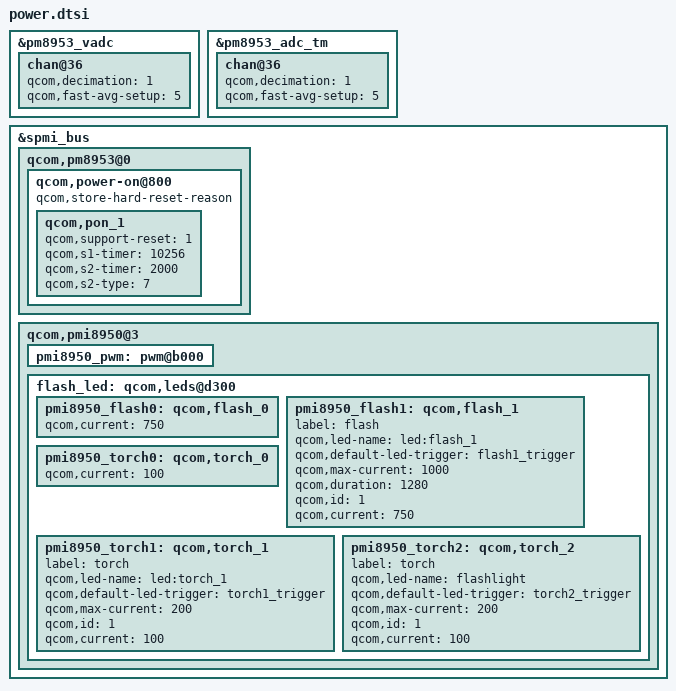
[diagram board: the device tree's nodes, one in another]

/* pm8953.dtsi */
&pm8953_vadc{
	chan@36 {
		qcom,decimation = <1>;
		qcom,fast-avg-setup = <5>;
	};
};
&pm8953_adc_tm{
	chan@36 {
		qcom,decimation = <1>;
		qcom,fast-avg-setup = <5>;
	};
};

&spmi_bus {
    /* pm8953.dtsi */
    /delete-node/ qcom,pm8953_typec@bf00;
	qcom,pm8953@0 {
		qcom,power-on@800 {
			qcom,store-hard-reset-reason;
			qcom,pon_1 {
				qcom,support-reset = <1>;
				qcom,s1-timer = <10256>;
				qcom,s2-timer = <2000>;
				qcom,s2-type = <7>;
		    };
	    };
    };
    /* pmi8950.dtsi */
    qcom,pmi8950@3 {

        pmi8950_pwm: pwm@b000 {
            status = "okay";
        };
        flash_led: qcom,leds@d300 {
            pmi8950_flash0: qcom,flash_0 {
                qcom,current = <750>;
            };
            pmi8950_flash1: qcom,flash_1 {
                label = "flash";
                qcom,led-name = "led:flash_1";
                qcom,default-led-trigger = "flash1_trigger";
                qcom,max-current = <1000>;
                qcom,duration = <1280>;
                qcom,id = <1>;
                qcom,current = <750>;
            };
            pmi8950_torch0: qcom,torch_0 {
                qcom,current = <100>;
            };
            pmi8950_torch1: qcom,torch_1 {
                label = "torch";
                qcom,led-name = "led:torch_1";
                qcom,default-led-trigger = "torch1_trigger";
                qcom,max-current = <200>;
                qcom,id = <1>;
                qcom,current = <100>;
            };
            pmi8950_torch2: qcom,torch_2 {
				label = "torch";
				qcom,led-name = "flashlight";
				qcom,default-led-trigger = "torch2_trigger";
				qcom,max-current = <200>;
				qcom,id = <1>;
				qcom,current = <100>;
            };
        };
        
    };
};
